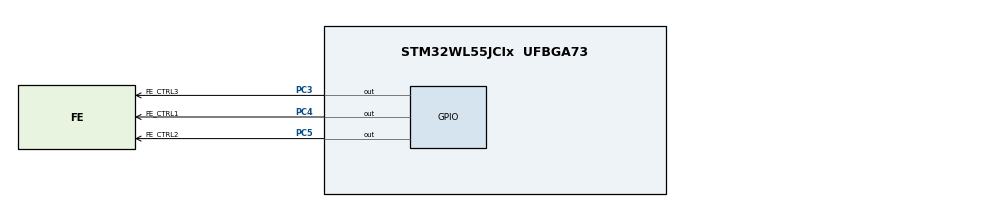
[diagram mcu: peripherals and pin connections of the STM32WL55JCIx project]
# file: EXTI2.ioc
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Mcu.Family=STM32WL
Mcu.Name=STM32WL55JCIx
Mcu.Package=UFBGA73
NUCLEO-WL55JC1.BUTTON=1
NUCLEO-WL55JC1.BUTTON2=1
NUCLEO-WL55JC1.BUTTON3=1
NUCLEO-WL55JC1.LD1=true
NUCLEO-WL55JC1.LD2=true
NUCLEO-WL55JC1.LD3=true
NUCLEO-WL55JC1.VCP=true
NVIC.EXTI0_IRQn=true\:0\:0\:false\:false\:true\:false\:true\:true
NVIC.EXTI1_IRQn=true\:0\:0\:false\:false\:true\:false\:true\:true
NVIC.EXTI9_5_IRQn=true\:0\:0\:false\:false\:true\:false\:true\:true
NVIC.PriorityGroup=NVIC_PRIORITYGROUP_4
NVIC.RCC_IRQn=true\:0\:0\:false\:false\:true\:true\:false\:true
PA2.Signal=USART2_TX
PA3.Signal=USART2_RX
PC14-OSC32_IN.GPIO_Label=RCC_OSC32_IN
PC14-OSC32_IN.Signal=RCC_OSC32_IN
PC15-OSC32_OUT.GPIO_Label=RCC_OSC32_OUT
PC15-OSC32_OUT.Signal=RCC_OSC32_OUT
PC3.GPIO_Label=FE_CTRL3
PC3.GPIO_Speed=GPIO_SPEED_FREQ_VERY_HIGH
PC3.Signal=GPIO_Output
PC4.GPIO_Label=FE_CTRL1
PC4.GPIO_Speed=GPIO_SPEED_FREQ_VERY_HIGH
PC4.Signal=GPIO_Output
PC5.GPIO_Label=FE_CTRL2
PC5.GPIO_Speed=GPIO_SPEED_FREQ_VERY_HIGH
PC5.Signal=GPIO_Output
ProjectManager.HeapSize=0x200
ProjectManager.StackSize=0x400
ProjectManager.TargetToolchain=STM32CubeIDE
RCC.HSE_VALUE=32000000
RCC.HSI_VALUE=16000000
RCC.LSE_VALUE=32768
RCC.VCOOutputFreq_Value=32000000
VP_NUCLEO-WL55JC1_VS_BSP_COMMON.Mode=COMMON
board=NUCLEO-WL55JC1

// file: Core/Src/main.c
/* USER CODE BEGIN Header */
/**
  ******************************************************************************
  * @file           : main.c
  * @brief          : Main program body
  ******************************************************************************
  * @attention
  *
  * Copyright (c) 2026 STMicroelectronics.
  * All rights reserved.
  *
  * This software is licensed under terms that can be found in the LICENSE file
  * in the root directory of this software component.
  * If no LICENSE file comes with this software, it is provided AS-IS.
  *
  ******************************************************************************
  */
/* USER CODE END Header */
#include "main.h"

COM_InitTypeDef BspCOMInit;

void SystemClock_Config(void);
static void MX_GPIO_Init(void);

int main(void)
{

  /* MCU Configuration--------------------------------------------------------*/

  /* Reset of all peripherals, Initializes the Flash interface and the Systick. */
  HAL_Init();

  /* Configure the system clock */
  SystemClock_Config();

  /* Initialize all configured peripherals */
  MX_GPIO_Init();

  /* Initialize leds */
  BSP_LED_Init(LED_BLUE);
  BSP_LED_Init(LED_GREEN);
  BSP_LED_Init(LED_RED);

  /* Initialize USER push-button, will be used to trigger an interrupt each time it's pressed.*/
  BSP_PB_Init(BUTTON_SW1, BUTTON_MODE_EXTI);
  BSP_PB_Init(BUTTON_SW2, BUTTON_MODE_EXTI);
  BSP_PB_Init(BUTTON_SW3, BUTTON_MODE_EXTI);

  /* Initialize COM1 port (115200, 8 bits (7-bit data + 1 stop bit), no parity */
  BspCOMInit.BaudRate   = 115200;
  BspCOMInit.WordLength = COM_WORDLENGTH_8B;
  BspCOMInit.StopBits   = COM_STOPBITS_1;
  BspCOMInit.Parity     = COM_PARITY_NONE;
  BspCOMInit.HwFlowCtl  = COM_HWCONTROL_NONE;
  if (BSP_COM_Init(COM1, &BspCOMInit) != BSP_ERROR_NONE)
  {
    Error_Handler();
  }

  /* Infinite loop */
  while (1)
  {

  }
}

void SystemClock_Config(void)
{
  RCC_OscInitTypeDef RCC_OscInitStruct = {0};
  RCC_ClkInitTypeDef RCC_ClkInitStruct = {0};

  /** Configure the main internal regulator output voltage
  */
  __HAL_PWR_VOLTAGESCALING_CONFIG(PWR_REGULATOR_VOLTAGE_SCALE2);

  /** Initializes the CPU, AHB and APB buses clocks
  */
  RCC_OscInitStruct.OscillatorType = RCC_OSCILLATORTYPE_MSI;
  RCC_OscInitStruct.MSIState = RCC_MSI_ON;
  RCC_OscInitStruct.MSICalibrationValue = RCC_MSICALIBRATION_DEFAULT;
  RCC_OscInitStruct.MSIClockRange = RCC_MSIRANGE_6;
  RCC_OscInitStruct.PLL.PLLState = RCC_PLL_NONE;
  if (HAL_RCC_OscConfig(&RCC_OscInitStruct) != HAL_OK)
  {
    Error_Handler();
  }

  /** Configure the SYSCLKSource, HCLK, PCLK1 and PCLK2 clocks dividers
  */
  RCC_ClkInitStruct.ClockType = RCC_CLOCKTYPE_HCLK3|RCC_CLOCKTYPE_HCLK
                              |RCC_CLOCKTYPE_SYSCLK|RCC_CLOCKTYPE_PCLK1
                              |RCC_CLOCKTYPE_PCLK2;
  RCC_ClkInitStruct.SYSCLKSource = RCC_SYSCLKSOURCE_MSI;
  RCC_ClkInitStruct.AHBCLKDivider = RCC_SYSCLK_DIV1;
  RCC_ClkInitStruct.APB1CLKDivider = RCC_HCLK_DIV1;
  RCC_ClkInitStruct.APB2CLKDivider = RCC_HCLK_DIV1;
  RCC_ClkInitStruct.AHBCLK3Divider = RCC_SYSCLK_DIV1;

  if (HAL_RCC_ClockConfig(&RCC_ClkInitStruct, FLASH_LATENCY_0) != HAL_OK)
  {
    Error_Handler();
  }
}

static void MX_GPIO_Init(void)
{
  GPIO_InitTypeDef GPIO_InitStruct = {0};

  /* GPIO Ports Clock Enable */
  __HAL_RCC_GPIOC_CLK_ENABLE();

  /*Configure GPIO pin Output Level */
  HAL_GPIO_WritePin(GPIOC, FE_CTRL3_Pin|FE_CTRL2_Pin|FE_CTRL1_Pin, GPIO_PIN_RESET);

  /*Configure GPIO pins : FE_CTRL3_Pin FE_CTRL2_Pin FE_CTRL1_Pin */
  GPIO_InitStruct.Pin = FE_CTRL3_Pin|FE_CTRL2_Pin|FE_CTRL1_Pin;
  GPIO_InitStruct.Mode = GPIO_MODE_OUTPUT_PP;
  GPIO_InitStruct.Pull = GPIO_NOPULL;
  GPIO_InitStruct.Speed = GPIO_SPEED_FREQ_VERY_HIGH;
  HAL_GPIO_Init(GPIOC, &GPIO_InitStruct);

}

/* USER CODE BEGIN 4 */
BSP_PB_Callback(Button_TypeDef Button)
{
	if (Button == BUTTON_SW1)
		BSP_LED_Toggle(LED1);
}

/* USER CODE END 4 */

void Error_Handler(void)
{
  __disable_irq();
  while (1)
  {
  }
}
